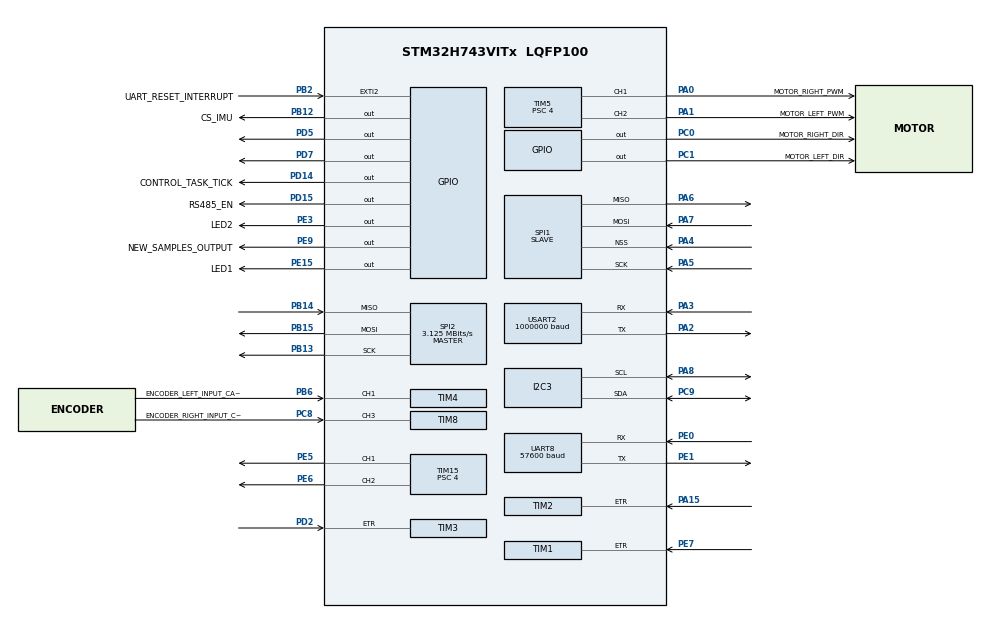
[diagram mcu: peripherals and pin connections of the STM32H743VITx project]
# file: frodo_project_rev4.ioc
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CORTEX_M7.default_mode_Activation=0
Dma.MEMTOMEM.4.Direction=DMA_MEMORY_TO_MEMORY
Dma.MEMTOMEM.4.EventEnable=DISABLE
Dma.MEMTOMEM.4.FIFOMode=DMA_FIFOMODE_ENABLE
Dma.MEMTOMEM.4.FIFOThreshold=DMA_FIFO_THRESHOLD_FULL
Dma.MEMTOMEM.4.Instance=DMA2_Stream0
Dma.MEMTOMEM.4.MemBurst=DMA_MBURST_SINGLE
Dma.MEMTOMEM.4.MemDataAlignment=DMA_MDATAALIGN_BYTE
Dma.MEMTOMEM.4.MemInc=DMA_MINC_ENABLE
Dma.MEMTOMEM.4.Mode=DMA_NORMAL
Dma.MEMTOMEM.4.PeriphBurst=DMA_PBURST_SINGLE
Dma.MEMTOMEM.4.PeriphDataAlignment=DMA_PDATAALIGN_BYTE
Dma.MEMTOMEM.4.PeriphInc=DMA_PINC_ENABLE
Dma.MEMTOMEM.4.Polarity=HAL_DMAMUX_REQ_GEN_RISING
Dma.MEMTOMEM.4.Priority=DMA_PRIORITY_VERY_HIGH
Dma.MEMTOMEM.4.RequestNumber=1
Dma.MEMTOMEM.4.SignalID=NONE
Dma.MEMTOMEM.4.SyncEnable=DISABLE
Dma.MEMTOMEM.4.SyncPolarity=HAL_DMAMUX_SYNC_NO_EVENT
Dma.MEMTOMEM.4.SyncRequestNumber=1
Dma.MEMTOMEM.4.SyncSignalID=NONE
Dma.Request0=UART8_RX
Dma.Request1=UART8_TX
Dma.Request2=USART2_RX
Dma.Request3=USART2_TX
Dma.Request4=MEMTOMEM
Dma.Request5=SPI1_RX
Dma.Request6=SPI1_TX
Dma.SPI1_RX.5.Direction=DMA_PERIPH_TO_MEMORY
Dma.SPI1_RX.5.EventEnable=DISABLE
Dma.SPI1_RX.5.FIFOMode=DMA_FIFOMODE_DISABLE
Dma.SPI1_RX.5.Instance=DMA1_Stream6
Dma.SPI1_RX.5.MemDataAlignment=DMA_MDATAALIGN_BYTE
Dma.SPI1_RX.5.MemInc=DMA_MINC_ENABLE
Dma.SPI1_RX.5.Mode=DMA_NORMAL
Dma.SPI1_RX.5.PeriphDataAlignment=DMA_PDATAALIGN_BYTE
Dma.SPI1_RX.5.PeriphInc=DMA_PINC_DISABLE
Dma.SPI1_RX.5.Polarity=HAL_DMAMUX_REQ_GEN_RISING
Dma.SPI1_RX.5.Priority=DMA_PRIORITY_LOW
Dma.SPI1_RX.5.RequestNumber=1
Dma.SPI1_RX.5.SignalID=NONE
Dma.SPI1_RX.5.SyncEnable=DISABLE
Dma.SPI1_RX.5.SyncPolarity=HAL_DMAMUX_SYNC_NO_EVENT
Dma.SPI1_RX.5.SyncRequestNumber=1
Dma.SPI1_RX.5.SyncSignalID=NONE
Dma.SPI1_TX.6.Direction=DMA_MEMORY_TO_PERIPH
Dma.SPI1_TX.6.EventEnable=DISABLE
Dma.SPI1_TX.6.FIFOMode=DMA_FIFOMODE_DISABLE
Dma.SPI1_TX.6.Instance=DMA1_Stream7
Dma.SPI1_TX.6.MemDataAlignment=DMA_MDATAALIGN_BYTE
Dma.SPI1_TX.6.MemInc=DMA_MINC_ENABLE
Dma.SPI1_TX.6.Mode=DMA_NORMAL
Dma.SPI1_TX.6.PeriphDataAlignment=DMA_PDATAALIGN_BYTE
Dma.SPI1_TX.6.PeriphInc=DMA_PINC_DISABLE
Dma.SPI1_TX.6.Polarity=HAL_DMAMUX_REQ_GEN_RISING
Dma.SPI1_TX.6.Priority=DMA_PRIORITY_LOW
Dma.SPI1_TX.6.RequestNumber=1
Dma.SPI1_TX.6.SignalID=NONE
Dma.SPI1_TX.6.SyncEnable=DISABLE
Dma.SPI1_TX.6.SyncPolarity=HAL_DMAMUX_SYNC_NO_EVENT
Dma.SPI1_TX.6.SyncRequestNumber=1
Dma.SPI1_TX.6.SyncSignalID=NONE
Dma.UART8_RX.0.Direction=DMA_PERIPH_TO_MEMORY
Dma.UART8_RX.0.EventEnable=DISABLE
Dma.UART8_RX.0.FIFOMode=DMA_FIFOMODE_DISABLE
Dma.UART8_RX.0.Instance=DMA1_Stream2
Dma.UART8_RX.0.MemDataAlignment=DMA_MDATAALIGN_BYTE
Dma.UART8_RX.0.MemInc=DMA_MINC_ENABLE
Dma.UART8_RX.0.Mode=DMA_NORMAL
Dma.UART8_RX.0.PeriphDataAlignment=DMA_PDATAALIGN_BYTE
Dma.UART8_RX.0.PeriphInc=DMA_PINC_DISABLE
Dma.UART8_RX.0.Polarity=HAL_DMAMUX_REQ_GEN_RISING
Dma.UART8_RX.0.Priority=DMA_PRIORITY_LOW
Dma.UART8_RX.0.RequestNumber=1
Dma.UART8_RX.0.SignalID=NONE
Dma.UART8_RX.0.SyncEnable=DISABLE
Dma.UART8_RX.0.SyncPolarity=HAL_DMAMUX_SYNC_NO_EVENT
Dma.UART8_RX.0.SyncRequestNumber=1
Dma.UART8_RX.0.SyncSignalID=NONE
Dma.UART8_TX.1.Direction=DMA_MEMORY_TO_PERIPH
Dma.UART8_TX.1.EventEnable=DISABLE
Dma.UART8_TX.1.FIFOMode=DMA_FIFOMODE_DISABLE
Dma.UART8_TX.1.Instance=DMA1_Stream3
Dma.UART8_TX.1.MemDataAlignment=DMA_MDATAALIGN_BYTE
Dma.UART8_TX.1.MemInc=DMA_MINC_ENABLE
Dma.UART8_TX.1.Mode=DMA_NORMAL
Dma.UART8_TX.1.PeriphDataAlignment=DMA_PDATAALIGN_BYTE
Dma.UART8_TX.1.PeriphInc=DMA_PINC_DISABLE
Dma.UART8_TX.1.Polarity=HAL_DMAMUX_REQ_GEN_RISING
Dma.UART8_TX.1.Priority=DMA_PRIORITY_LOW
Dma.UART8_TX.1.RequestNumber=1
Dma.UART8_TX.1.SignalID=NONE
Dma.UART8_TX.1.SyncEnable=DISABLE
Dma.UART8_TX.1.SyncPolarity=HAL_DMAMUX_SYNC_NO_EVENT
Dma.UART8_TX.1.SyncRequestNumber=1
Dma.UART8_TX.1.SyncSignalID=NONE
Dma.USART2_RX.2.Direction=DMA_PERIPH_TO_MEMORY
Dma.USART2_RX.2.EventEnable=DISABLE
Dma.USART2_RX.2.FIFOMode=DMA_FIFOMODE_DISABLE
Dma.USART2_RX.2.Instance=DMA1_Stream4
Dma.USART2_RX.2.MemDataAlignment=DMA_MDATAALIGN_BYTE
Dma.USART2_RX.2.MemInc=DMA_MINC_ENABLE
Dma.USART2_RX.2.Mode=DMA_NORMAL
Dma.USART2_RX.2.PeriphDataAlignment=DMA_PDATAALIGN_BYTE
Dma.USART2_RX.2.PeriphInc=DMA_PINC_DISABLE
Dma.USART2_RX.2.Polarity=HAL_DMAMUX_REQ_GEN_RISING
Dma.USART2_RX.2.Priority=DMA_PRIORITY_LOW
Dma.USART2_RX.2.RequestNumber=1
Dma.USART2_RX.2.SignalID=NONE
Dma.USART2_RX.2.SyncEnable=DISABLE
Dma.USART2_RX.2.SyncPolarity=HAL_DMAMUX_SYNC_NO_EVENT
Dma.USART2_RX.2.SyncRequestNumber=1
Dma.USART2_RX.2.SyncSignalID=NONE
Dma.USART2_TX.3.Direction=DMA_MEMORY_TO_PERIPH
Dma.USART2_TX.3.EventEnable=DISABLE
Dma.USART2_TX.3.FIFOMode=DMA_FIFOMODE_DISABLE
Dma.USART2_TX.3.Instance=DMA1_Stream5
Dma.USART2_TX.3.MemDataAlignment=DMA_MDATAALIGN_BYTE
Dma.USART2_TX.3.MemInc=DMA_MINC_ENABLE
Dma.USART2_TX.3.Mode=DMA_NORMAL
Dma.USART2_TX.3.PeriphDataAlignment=DMA_PDATAALIGN_BYTE
Dma.USART2_TX.3.PeriphInc=DMA_PINC_DISABLE
Dma.USART2_TX.3.Polarity=HAL_DMAMUX_REQ_GEN_RISING
Dma.USART2_TX.3.Priority=DMA_PRIORITY_LOW
Dma.USART2_TX.3.RequestNumber=1
Dma.USART2_TX.3.SignalID=NONE
Dma.USART2_TX.3.SyncEnable=DISABLE
Dma.USART2_TX.3.SyncPolarity=HAL_DMAMUX_SYNC_NO_EVENT
Dma.USART2_TX.3.SyncRequestNumber=1
Dma.USART2_TX.3.SyncSignalID=NONE
FREERTOS.Tasks01=defaultTask,24,128,StartDefaultTask,Default,NULL,Dynamic,NULL,NULL
FREERTOS.Timers01=myTimer02,Callback01,osTimerPeriodic,Default,NULL,Dynamic,NULL
FREERTOS.configTOTAL_HEAP_SIZE=120000
FREERTOS.configUSE_NEWLIB_REENTRANT=1
I2C3.I2C_Rise_Time=0
I2C3.Timing=0x10C0ECFF
Mcu.Family=STM32H7
Mcu.Name=STM32H743VITx
Mcu.Package=LQFP100
NVIC.DMA1_Stream2_IRQn=true\:5\:0\:false\:false\:true\:true\:false\:true\:true
NVIC.DMA1_Stream3_IRQn=true\:5\:0\:false\:false\:true\:true\:false\:true\:true
NVIC.DMA1_Stream4_IRQn=true\:5\:0\:false\:false\:true\:true\:false\:true\:true
NVIC.DMA1_Stream5_IRQn=true\:5\:0\:false\:false\:true\:true\:false\:true\:true
NVIC.DMA1_Stream6_IRQn=true\:5\:0\:false\:false\:true\:true\:false\:true\:true
NVIC.DMA1_Stream7_IRQn=true\:5\:0\:false\:false\:true\:true\:false\:true\:true
NVIC.DMA2_Stream0_IRQn=true\:5\:0\:false\:false\:true\:true\:true\:true\:true
NVIC.EXTI2_IRQn=true\:5\:0\:false\:false\:true\:true\:true\:true\:true
NVIC.I2C3_ER_IRQn=true\:5\:0\:false\:false\:true\:true\:true\:true\:true
NVIC.I2C3_EV_IRQn=true\:5\:0\:false\:false\:true\:true\:true\:true\:true
NVIC.PriorityGroup=NVIC_PRIORITYGROUP_4
NVIC.SPI1_IRQn=true\:5\:0\:false\:false\:true\:true\:true\:true\:true
NVIC.TIM2_IRQn=true\:5\:0\:false\:false\:true\:true\:true\:true\:true
NVIC.TIM4_IRQn=true\:5\:0\:false\:false\:true\:true\:true\:true\:true
NVIC.TIM6_DAC_IRQn=true\:15\:0\:false\:false\:true\:false\:false\:true\:true
NVIC.TimeBase=TIM6_DAC_IRQn
NVIC.TimeBaseIP=TIM6
NVIC.UART8_IRQn=true\:5\:0\:false\:false\:true\:true\:true\:true\:true
NVIC.USART2_IRQn=true\:5\:0\:false\:false\:true\:true\:true\:true\:true
PA0.GPIO_Label=MOTOR_RIGHT_PWM
PA0.Signal=S_TIM5_CH1
PA1.GPIO_Label=MOTOR_LEFT_PWM
PA1.Signal=S_TIM5_CH2
PA10.Signal=USART1_RX
PA13\ (JTMS/SWDIO).Mode=Serial_Wire
PA13\ (JTMS/SWDIO).Signal=DEBUG_JTMS-SWDIO
PA14\ (JTCK/SWCLK).Mode=Serial_Wire
PA14\ (JTCK/SWCLK).Signal=DEBUG_JTCK-SWCLK
PA15\ (JTDI).Signal=S_TIM2_CH1_ETR
PA2.Mode=Asynchronous
PA2.Signal=USART2_TX
PA3.Mode=Asynchronous
PA3.Signal=USART2_RX
PA4.Mode=NSS_Signal_Hard_Input
PA4.Signal=SPI1_NSS
PA5.Mode=Full_Duplex_Slave
PA5.Signal=SPI1_SCK
PA6.Mode=Full_Duplex_Slave
PA6.Signal=SPI1_MISO
PA7.Mode=Full_Duplex_Slave
PA7.Signal=SPI1_MOSI
PA8.Mode=I2C
PA8.Signal=I2C3_SCL
PA9.Signal=USART1_TX
PB12.GPIO_Label=CS_IMU
PB12.Signal=GPIO_Output
PB13.Mode=Full_Duplex_Master
PB13.Signal=SPI2_SCK
PB14.Mode=Full_Duplex_Master
PB14.Signal=SPI2_MISO
PB15.Mode=Full_Duplex_Master
PB15.Signal=SPI2_MOSI
PB2.GPIO_Label=UART_RESET_INTERRUPT
PB2.GPIO_ModeDefaultEXTI=GPIO_MODE_IT_RISING_FALLING
PB2.GPIO_PuPd=GPIO_PULLDOWN
PB2.Signal=GPXTI2
PB6.GPIO_Label=ENCODER_LEFT_INPUT_CAPTURE
PB6.Signal=S_TIM4_CH1
PC0.GPIO_Label=MOTOR_RIGHT_DIR
PC0.Signal=GPIO_Output
PC1.GPIO_Label=MOTOR_LEFT_DIR
PC1.Signal=GPIO_Output
PC8.GPIO_Label=ENCODER_RIGHT_INPUT_CAPTURE
PC8.Signal=S_TIM8_CH3
PC9.Mode=I2C
PC9.Signal=I2C3_SDA
PD14.GPIO_Label=CONTROL_TASK_TICK
PD14.Signal=GPIO_Output
PD15.GPIO_Label=RS485_EN
PD15.Signal=GPIO_Output
PD2.Signal=S_TIM3_ETR
PD5.Signal=GPIO_Output
PD7.Signal=GPIO_Output
PE0.Mode=Asynchronous
PE0.Signal=UART8_RX
PE1.Mode=Asynchronous
PE1.Signal=UART8_TX
PE15.GPIO_Label=LED1
PE15.Signal=GPIO_Output
PE3.GPIO_Label=LED2
PE3.Signal=GPIO_Output
PE5.Signal=S_TIM15_CH1
PE6.Signal=S_TIM15_CH2
PE7.Signal=S_TIM1_ETR
PE9.GPIO_Label=NEW_SAMPLES_OUTPUT
PE9.GPIO_PuPd=GPIO_PULLDOWN
PE9.Signal=GPIO_Output
PH0-OSC_IN\ (PH0).Mode=HSE-External-Oscillator
PH0-OSC_IN\ (PH0).Signal=RCC_OSC_IN
PH1-OSC_OUT\ (PH1).Mode=HSE-External-Oscillator
PH1-OSC_OUT\ (PH1).Signal=RCC_OSC_OUT
ProjectManager.HeapSize=0x200
ProjectManager.StackSize=0x400
ProjectManager.TargetToolchain=STM32CubeIDE
RCC.ADCFreq_Value=75000000
RCC.APB1Freq_Value=100000000
RCC.APB2Freq_Value=100000000
RCC.APB3Freq_Value=100000000
RCC.APB4Freq_Value=100000000
RCC.CortexFreq_Value=400000000
RCC.D1PPRE=RCC_APB3_DIV2
RCC.D2PPRE1=RCC_APB1_DIV2
RCC.D2PPRE2=RCC_APB2_DIV2
RCC.D3PPRE=RCC_APB4_DIV2
RCC.DIVM1=2
RCC.DIVM2=2
RCC.DIVN1=64
RCC.DIVN2=12
RCC.DIVQ1=4
RCC.FDCANCLockSelection=RCC_FDCANCLKSOURCE_PLL2
RCC.HCLKFreq_Value=200000000
RCC.HPRE=RCC_HCLK_DIV2
RCC.PLL2FRACN=0
RCC.PLLFRACN=0
RCC.PLLSourceVirtual=RCC_PLLSOURCE_HSE
RCC.PWR_Regulator_Voltage_Scale=PWR_REGULATOR_VOLTAGE_SCALE1
RCC.SYSCLKFreq_VALUE=400000000
RCC.SYSCLKSource=RCC_SYSCLKSOURCE_PLLCLK
RCC.USBFreq_Value=200000000
SH.S_TIM15_CH1.0=TIM15_CH1,PWM Generation1 CH1
SH.S_TIM15_CH2.0=TIM15_CH2,PWM Generation2 CH2
SH.S_TIM1_ETR.0=TIM1_ETR,TriggerSource_ETR
SH.S_TIM2_CH1_ETR.0=TIM2_ETR,TriggerSource_ETR
SH.S_TIM3_ETR.0=TIM3_ETR,TriggerSource_ETR
SH.S_TIM4_CH1.0=TIM4_CH1,Input_Capture1_from_TI1
SH.S_TIM5_CH1.0=TIM5_CH1,PWM Generation1 CH1
SH.S_TIM5_CH2.0=TIM5_CH2,PWM Generation2 CH2
SH.S_TIM8_CH3.0=TIM8_CH3,Input_Capture3_from_TI3
SPI1.DataSize=SPI_DATASIZE_8BIT
SPI1.Direction=SPI_DIRECTION_2LINES
SPI1.Mode=SPI_MODE_SLAVE
SPI1.VirtualNSS=VM_NSSHARD
SPI1.VirtualType=VM_SLAVE
SPI2.BaudRatePrescaler=SPI_BAUDRATEPRESCALER_64
SPI2.CalculateBaudRate=3.125 MBits/s
SPI2.DataSize=SPI_DATASIZE_8BIT
SPI2.Direction=SPI_DIRECTION_2LINES
SPI2.Mode=SPI_MODE_MASTER
SPI2.VirtualType=VM_MASTER
TIM15.Channel-PWM\ Generation1\ CH1=TIM_CHANNEL_1
TIM15.Channel-PWM\ Generation2\ CH2=TIM_CHANNEL_2
TIM15.Period=40000
TIM15.Prescaler=4
TIM4.Channel-Input_Capture1_from_TI1=TIM_CHANNEL_1
TIM4.ICPolarity_CH1=TIM_INPUTCHANNELPOLARITY_RISING
TIM4.Prescaler=199
TIM5.Channel-PWM\ Generation1\ CH1=TIM_CHANNEL_1
TIM5.Channel-PWM\ Generation2\ CH2=TIM_CHANNEL_2
TIM5.Period=40000
TIM5.Prescaler=4
TIM8.Channel-Input_Capture3_from_TI3=TIM_CHANNEL_3
TIM8.Prescaler=199
UART8.BaudRate=57600
UART8.Parity=PARITY_EVEN
UART8.WordLength=WORDLENGTH_9B
USART2.BaudRate=1000000
USART2.VirtualMode-Asynchronous=VM_ASYNC
VP_FREERTOS_VS_CMSIS_V2.Mode=CMSIS_V2
VP_MEMORYMAP_VS_MEMORYMAP.Mode=CurAppReg
VP_SYS_VS_tim6.Mode=TIM6
VP_TIM1_VS_ControllerModeClock.Mode=Clock Mode
VP_TIM2_VS_ControllerModeClock.Mode=Clock Mode
VP_TIM3_VS_ControllerModeClock.Mode=Clock Mode
VP_TIM4_VS_ClockSourceINT.Mode=Internal
VP_TIM5_VS_ClockSourceINT.Mode=Internal
VP_TIM8_VS_ClockSourceINT.Mode=Internal
board=custom

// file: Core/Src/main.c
/* USER CODE BEGIN Header */
/**
  ******************************************************************************
  * @file           : main.c
  * @brief          : Main program body
  ******************************************************************************
  * @attention
  *
  * Copyright (c) 2025 STMicroelectronics.
  * All rights reserved.
  *
  * This software is licensed under terms that can be found in the LICENSE file
  * in the root directory of this software component.
  * If no LICENSE file comes with this software, it is provided AS-IS.
  *
  ******************************************************************************
  */
/* USER CODE END Header */
#include "main.h"
#include "cmsis_os.h"

I2C_HandleTypeDef hi2c3;

SPI_HandleTypeDef hspi1;
SPI_HandleTypeDef hspi2;
DMA_HandleTypeDef hdma_spi1_rx;
DMA_HandleTypeDef hdma_spi1_tx;

TIM_HandleTypeDef htim1;
TIM_HandleTypeDef htim2;
TIM_HandleTypeDef htim3;
TIM_HandleTypeDef htim4;
TIM_HandleTypeDef htim5;
TIM_HandleTypeDef htim8;
TIM_HandleTypeDef htim15;

UART_HandleTypeDef huart8;
UART_HandleTypeDef huart2;
DMA_HandleTypeDef hdma_uart8_rx;
DMA_HandleTypeDef hdma_uart8_tx;
DMA_HandleTypeDef hdma_usart2_rx;
DMA_HandleTypeDef hdma_usart2_tx;

DMA_HandleTypeDef hdma_memtomem_dma2_stream0;
/* Definitions for defaultTask */
osThreadId_t defaultTaskHandle;
const osThreadAttr_t defaultTask_attributes = {
  .name = "defaultTask",
  .stack_size = 128 * 4,
  .priority = (osPriority_t) osPriorityNormal,
};
/* Definitions for myTimer02 */
osTimerId_t myTimer02Handle;
const osTimerAttr_t myTimer02_attributes = {
  .name = "myTimer02"
};

void SystemClock_Config(void);
static void MX_GPIO_Init(void);
static void MX_DMA_Init(void);
static void MX_SPI2_Init(void);
static void MX_UART8_Init(void);
static void MX_USART2_UART_Init(void);
static void MX_TIM2_Init(void);
static void MX_SPI1_Init(void);
static void MX_I2C3_Init(void);
static void MX_TIM5_Init(void);
static void MX_TIM3_Init(void);
static void MX_TIM4_Init(void);
static void MX_TIM8_Init(void);
static void MX_TIM15_Init(void);
static void MX_TIM1_Init(void);
void StartDefaultTask(void *argument);
void Callback01(void *argument);

int main(void)
{

  /* MCU Configuration--------------------------------------------------------*/

  /* Reset of all peripherals, Initializes the Flash interface and the Systick. */
  HAL_Init();

  /* Configure the system clock */
  SystemClock_Config();

  /* Initialize all configured peripherals */
  MX_GPIO_Init();
  MX_DMA_Init();
  MX_SPI2_Init();
  MX_UART8_Init();
  MX_USART2_UART_Init();
  MX_TIM2_Init();
  MX_SPI1_Init();
  MX_I2C3_Init();
  MX_TIM5_Init();
  MX_TIM3_Init();
  MX_TIM4_Init();
  MX_TIM8_Init();
  MX_TIM15_Init();
  MX_TIM1_Init();

  /* Init scheduler */
  osKernelInitialize();

  /* Create the timer(s) */
  /* creation of myTimer02 */
  myTimer02Handle = osTimerNew(Callback01, osTimerPeriodic, NULL, &myTimer02_attributes);

  /* USER CODE BEGIN RTOS_QUEUES */
  firmware();
  /* add queues, ... */
  /* USER CODE END RTOS_QUEUES */

  /* Create the thread(s) */
  /* creation of defaultTask */
  defaultTaskHandle = osThreadNew(StartDefaultTask, NULL, &defaultTask_attributes);

  /* Start scheduler */
  osKernelStart();

  /* We should never get here as control is now taken by the scheduler */

  /* Infinite loop */
  while (1)
  {

  }
}

void SystemClock_Config(void)
{
  RCC_OscInitTypeDef RCC_OscInitStruct = {0};
  RCC_ClkInitTypeDef RCC_ClkInitStruct = {0};

  /** Supply configuration update enable
  */
  HAL_PWREx_ConfigSupply(PWR_LDO_SUPPLY);

  /** Configure the main internal regulator output voltage
  */
  __HAL_PWR_VOLTAGESCALING_CONFIG(PWR_REGULATOR_VOLTAGE_SCALE1);

  while(!__HAL_PWR_GET_FLAG(PWR_FLAG_VOSRDY)) {}

  /** Initializes the RCC Oscillators according to the specified parameters
  * in the RCC_OscInitTypeDef structure.
  */
  RCC_OscInitStruct.OscillatorType = RCC_OSCILLATORTYPE_HSE;
  RCC_OscInitStruct.HSEState = RCC_HSE_ON;
  RCC_OscInitStruct.PLL.PLLState = RCC_PLL_ON;
  RCC_OscInitStruct.PLL.PLLSource = RCC_PLLSOURCE_HSE;
  RCC_OscInitStruct.PLL.PLLM = 2;
  RCC_OscInitStruct.PLL.PLLN = 64;
  RCC_OscInitStruct.PLL.PLLP = 2;
  RCC_OscInitStruct.PLL.PLLQ = 4;
  RCC_OscInitStruct.PLL.PLLR = 2;
  RCC_OscInitStruct.PLL.PLLRGE = RCC_PLL1VCIRANGE_3;
  RCC_OscInitStruct.PLL.PLLVCOSEL = RCC_PLL1VCOWIDE;
  RCC_OscInitStruct.PLL.PLLFRACN = 0;
  if (HAL_RCC_OscConfig(&RCC_OscInitStruct) != HAL_OK)
  {
    Error_Handler();
  }

  /** Initializes the CPU, AHB and APB buses clocks
  */
  RCC_ClkInitStruct.ClockType = RCC_CLOCKTYPE_HCLK|RCC_CLOCKTYPE_SYSCLK
                              |RCC_CLOCKTYPE_PCLK1|RCC_CLOCKTYPE_PCLK2
                              |RCC_CLOCKTYPE_D3PCLK1|RCC_CLOCKTYPE_D1PCLK1;
  RCC_ClkInitStruct.SYSCLKSource = RCC_SYSCLKSOURCE_PLLCLK;
  RCC_ClkInitStruct.SYSCLKDivider = RCC_SYSCLK_DIV1;
  RCC_ClkInitStruct.AHBCLKDivider = RCC_HCLK_DIV2;
  RCC_ClkInitStruct.APB3CLKDivider = RCC_APB3_DIV2;
  RCC_ClkInitStruct.APB1CLKDivider = RCC_APB1_DIV2;
  RCC_ClkInitStruct.APB2CLKDivider = RCC_APB2_DIV2;
  RCC_ClkInitStruct.APB4CLKDivider = RCC_APB4_DIV2;

  if (HAL_RCC_ClockConfig(&RCC_ClkInitStruct, FLASH_LATENCY_2) != HAL_OK)
  {
    Error_Handler();
  }
}

static void MX_I2C3_Init(void)
{

  hi2c3.Instance = I2C3;
  hi2c3.Init.Timing = 0x10C0ECFF;
  hi2c3.Init.OwnAddress1 = 0;
  hi2c3.Init.AddressingMode = I2C_ADDRESSINGMODE_7BIT;
  hi2c3.Init.DualAddressMode = I2C_DUALADDRESS_DISABLE;
  hi2c3.Init.OwnAddress2 = 0;
  hi2c3.Init.OwnAddress2Masks = I2C_OA2_NOMASK;
  hi2c3.Init.GeneralCallMode = I2C_GENERALCALL_DISABLE;
  hi2c3.Init.NoStretchMode = I2C_NOSTRETCH_DISABLE;
  if (HAL_I2C_Init(&hi2c3) != HAL_OK)
  {
    Error_Handler();
  }

  /** Configure Analogue filter
  */
  if (HAL_I2CEx_ConfigAnalogFilter(&hi2c3, I2C_ANALOGFILTER_ENABLE) != HAL_OK)
  {
    Error_Handler();
  }

  /** Configure Digital filter
  */
  if (HAL_I2CEx_ConfigDigitalFilter(&hi2c3, 0) != HAL_OK)
  {
    Error_Handler();
  }

}

static void MX_SPI1_Init(void)
{

  /* SPI1 parameter configuration*/
  hspi1.Instance = SPI1;
  hspi1.Init.Mode = SPI_MODE_SLAVE;
  hspi1.Init.Direction = SPI_DIRECTION_2LINES;
  hspi1.Init.DataSize = SPI_DATASIZE_8BIT;
  hspi1.Init.CLKPolarity = SPI_POLARITY_LOW;
  hspi1.Init.CLKPhase = SPI_PHASE_1EDGE;
  hspi1.Init.NSS = SPI_NSS_HARD_INPUT;
  hspi1.Init.FirstBit = SPI_FIRSTBIT_MSB;
  hspi1.Init.TIMode = SPI_TIMODE_DISABLE;
  hspi1.Init.CRCCalculation = SPI_CRCCALCULATION_DISABLE;
  hspi1.Init.CRCPolynomial = 0x0;
  hspi1.Init.NSSPMode = SPI_NSS_PULSE_DISABLE;
  hspi1.Init.NSSPolarity = SPI_NSS_POLARITY_LOW;
  hspi1.Init.FifoThreshold = SPI_FIFO_THRESHOLD_01DATA;
  hspi1.Init.TxCRCInitializationPattern = SPI_CRC_INITIALIZATION_ALL_ZERO_PATTERN;
  hspi1.Init.RxCRCInitializationPattern = SPI_CRC_INITIALIZATION_ALL_ZERO_PATTERN;
  hspi1.Init.MasterSSIdleness = SPI_MASTER_SS_IDLENESS_00CYCLE;
  hspi1.Init.MasterInterDataIdleness = SPI_MASTER_INTERDATA_IDLENESS_00CYCLE;
  hspi1.Init.MasterReceiverAutoSusp = SPI_MASTER_RX_AUTOSUSP_DISABLE;
  hspi1.Init.MasterKeepIOState = SPI_MASTER_KEEP_IO_STATE_DISABLE;
  hspi1.Init.IOSwap = SPI_IO_SWAP_DISABLE;
  if (HAL_SPI_Init(&hspi1) != HAL_OK)
  {
    Error_Handler();
  }

}

static void MX_SPI2_Init(void)
{

  /* SPI2 parameter configuration*/
  hspi2.Instance = SPI2;
  hspi2.Init.Mode = SPI_MODE_MASTER;
  hspi2.Init.Direction = SPI_DIRECTION_2LINES;
  hspi2.Init.DataSize = SPI_DATASIZE_8BIT;
  hspi2.Init.CLKPolarity = SPI_POLARITY_LOW;
  hspi2.Init.CLKPhase = SPI_PHASE_1EDGE;
  hspi2.Init.NSS = SPI_NSS_SOFT;
  hspi2.Init.BaudRatePrescaler = SPI_BAUDRATEPRESCALER_64;
  hspi2.Init.FirstBit = SPI_FIRSTBIT_MSB;
  hspi2.Init.TIMode = SPI_TIMODE_DISABLE;
  hspi2.Init.CRCCalculation = SPI_CRCCALCULATION_DISABLE;
  hspi2.Init.CRCPolynomial = 0x0;
  hspi2.Init.NSSPMode = SPI_NSS_PULSE_ENABLE;
  hspi2.Init.NSSPolarity = SPI_NSS_POLARITY_LOW;
  hspi2.Init.FifoThreshold = SPI_FIFO_THRESHOLD_01DATA;
  hspi2.Init.TxCRCInitializationPattern = SPI_CRC_INITIALIZATION_ALL_ZERO_PATTERN;
  hspi2.Init.RxCRCInitializationPattern = SPI_CRC_INITIALIZATION_ALL_ZERO_PATTERN;
  hspi2.Init.MasterSSIdleness = SPI_MASTER_SS_IDLENESS_00CYCLE;
  hspi2.Init.MasterInterDataIdleness = SPI_MASTER_INTERDATA_IDLENESS_00CYCLE;
  hspi2.Init.MasterReceiverAutoSusp = SPI_MASTER_RX_AUTOSUSP_DISABLE;
  hspi2.Init.MasterKeepIOState = SPI_MASTER_KEEP_IO_STATE_DISABLE;
  hspi2.Init.IOSwap = SPI_IO_SWAP_DISABLE;
  if (HAL_SPI_Init(&hspi2) != HAL_OK)
  {
    Error_Handler();
  }

}

static void MX_TIM1_Init(void)
{

  TIM_SlaveConfigTypeDef sSlaveConfig = {0};
  TIM_MasterConfigTypeDef sMasterConfig = {0};

  htim1.Instance = TIM1;
  htim1.Init.Prescaler = 0;
  htim1.Init.CounterMode = TIM_COUNTERMODE_UP;
  htim1.Init.Period = 65535;
  htim1.Init.ClockDivision = TIM_CLOCKDIVISION_DIV1;
  htim1.Init.RepetitionCounter = 0;
  htim1.Init.AutoReloadPreload = TIM_AUTORELOAD_PRELOAD_DISABLE;
  if (HAL_TIM_Base_Init(&htim1) != HAL_OK)
  {
    Error_Handler();
  }
  sSlaveConfig.SlaveMode = TIM_SLAVEMODE_EXTERNAL1;
  sSlaveConfig.InputTrigger = TIM_TS_ETRF;
  sSlaveConfig.TriggerPolarity = TIM_TRIGGERPOLARITY_NONINVERTED;
  sSlaveConfig.TriggerPrescaler = TIM_TRIGGERPRESCALER_DIV1;
  sSlaveConfig.TriggerFilter = 0;
  if (HAL_TIM_SlaveConfigSynchro(&htim1, &sSlaveConfig) != HAL_OK)
  {
    Error_Handler();
  }
  sMasterConfig.MasterOutputTrigger = TIM_TRGO_RESET;
  sMasterConfig.MasterOutputTrigger2 = TIM_TRGO2_RESET;
  sMasterConfig.MasterSlaveMode = TIM_MASTERSLAVEMODE_DISABLE;
  if (HAL_TIMEx_MasterConfigSynchronization(&htim1, &sMasterConfig) != HAL_OK)
  {
    Error_Handler();
  }

}

static void MX_TIM2_Init(void)
{

  TIM_SlaveConfigTypeDef sSlaveConfig = {0};
  TIM_MasterConfigTypeDef sMasterConfig = {0};

  htim2.Instance = TIM2;
  htim2.Init.Prescaler = 0;
  htim2.Init.CounterMode = TIM_COUNTERMODE_UP;
  htim2.Init.Period = 4294967295;
  htim2.Init.ClockDivision = TIM_CLOCKDIVISION_DIV1;
  htim2.Init.AutoReloadPreload = TIM_AUTORELOAD_PRELOAD_DISABLE;
  if (HAL_TIM_Base_Init(&htim2) != HAL_OK)
  {
    Error_Handler();
  }
  sSlaveConfig.SlaveMode = TIM_SLAVEMODE_EXTERNAL1;
  sSlaveConfig.InputTrigger = TIM_TS_ETRF;
  sSlaveConfig.TriggerPolarity = TIM_TRIGGERPOLARITY_NONINVERTED;
  sSlaveConfig.TriggerPrescaler = TIM_TRIGGERPRESCALER_DIV1;
  sSlaveConfig.TriggerFilter = 0;
  if (HAL_TIM_SlaveConfigSynchro(&htim2, &sSlaveConfig) != HAL_OK)
  {
    Error_Handler();
  }
  sMasterConfig.MasterOutputTrigger = TIM_TRGO_RESET;
  sMasterConfig.MasterSlaveMode = TIM_MASTERSLAVEMODE_DISABLE;
  if (HAL_TIMEx_MasterConfigSynchronization(&htim2, &sMasterConfig) != HAL_OK)
  {
    Error_Handler();
  }

}

static void MX_TIM3_Init(void)
{

  TIM_SlaveConfigTypeDef sSlaveConfig = {0};
  TIM_MasterConfigTypeDef sMasterConfig = {0};

  htim3.Instance = TIM3;
  htim3.Init.Prescaler = 0;
  htim3.Init.CounterMode = TIM_COUNTERMODE_UP;
  htim3.Init.Period = 65535;
  htim3.Init.ClockDivision = TIM_CLOCKDIVISION_DIV1;
  htim3.Init.AutoReloadPreload = TIM_AUTORELOAD_PRELOAD_DISABLE;
  if (HAL_TIM_Base_Init(&htim3) != HAL_OK)
  {
    Error_Handler();
  }
  sSlaveConfig.SlaveMode = TIM_SLAVEMODE_EXTERNAL1;
  sSlaveConfig.InputTrigger = TIM_TS_ETRF;
  sSlaveConfig.TriggerPolarity = TIM_TRIGGERPOLARITY_NONINVERTED;
  sSlaveConfig.TriggerPrescaler = TIM_TRIGGERPRESCALER_DIV1;
  sSlaveConfig.TriggerFilter = 0;
  if (HAL_TIM_SlaveConfigSynchro(&htim3, &sSlaveConfig) != HAL_OK)
  {
    Error_Handler();
  }
  sMasterConfig.MasterOutputTrigger = TIM_TRGO_RESET;
  sMasterConfig.MasterSlaveMode = TIM_MASTERSLAVEMODE_DISABLE;
  if (HAL_TIMEx_MasterConfigSynchronization(&htim3, &sMasterConfig) != HAL_OK)
  {
    Error_Handler();
  }

}

static void MX_TIM4_Init(void)
{

  TIM_ClockConfigTypeDef sClockSourceConfig = {0};
  TIM_MasterConfigTypeDef sMasterConfig = {0};
  TIM_IC_InitTypeDef sConfigIC = {0};

  htim4.Instance = TIM4;
  htim4.Init.Prescaler = 199;
  htim4.Init.CounterMode = TIM_COUNTERMODE_UP;
  htim4.Init.Period = 65535;
  htim4.Init.ClockDivision = TIM_CLOCKDIVISION_DIV1;
  htim4.Init.AutoReloadPreload = TIM_AUTORELOAD_PRELOAD_DISABLE;
  if (HAL_TIM_Base_Init(&htim4) != HAL_OK)
  {
    Error_Handler();
  }
  sClockSourceConfig.ClockSource = TIM_CLOCKSOURCE_INTERNAL;
  if (HAL_TIM_ConfigClockSource(&htim4, &sClockSourceConfig) != HAL_OK)
  {
    Error_Handler();
  }
  if (HAL_TIM_IC_Init(&htim4) != HAL_OK)
  {
    Error_Handler();
  }
  sMasterConfig.MasterOutputTrigger = TIM_TRGO_RESET;
  sMasterConfig.MasterSlaveMode = TIM_MASTERSLAVEMODE_DISABLE;
  if (HAL_TIMEx_MasterConfigSynchronization(&htim4, &sMasterConfig) != HAL_OK)
  {
    Error_Handler();
  }
  sConfigIC.ICPolarity = TIM_INPUTCHANNELPOLARITY_RISING;
  sConfigIC.ICSelection = TIM_ICSELECTION_DIRECTTI;
  sConfigIC.ICPrescaler = TIM_ICPSC_DIV1;
  sConfigIC.ICFilter = 0;
  if (HAL_TIM_IC_ConfigChannel(&htim4, &sConfigIC, TIM_CHANNEL_1) != HAL_OK)
  {
    Error_Handler();
  }

}

static void MX_TIM5_Init(void)
{

  TIM_ClockConfigTypeDef sClockSourceConfig = {0};
  TIM_MasterConfigTypeDef sMasterConfig = {0};
  TIM_OC_InitTypeDef sConfigOC = {0};

  htim5.Instance = TIM5;
  htim5.Init.Prescaler = 4;
  htim5.Init.CounterMode = TIM_COUNTERMODE_UP;
  htim5.Init.Period = 40000;
  htim5.Init.ClockDivision = TIM_CLOCKDIVISION_DIV1;
  htim5.Init.AutoReloadPreload = TIM_AUTORELOAD_PRELOAD_DISABLE;
  if (HAL_TIM_Base_Init(&htim5) != HAL_OK)
  {
    Error_Handler();
  }
  sClockSourceConfig.ClockSource = TIM_CLOCKSOURCE_INTERNAL;
  if (HAL_TIM_ConfigClockSource(&htim5, &sClockSourceConfig) != HAL_OK)
  {
    Error_Handler();
  }
  if (HAL_TIM_PWM_Init(&htim5) != HAL_OK)
  {
    Error_Handler();
  }
  sMasterConfig.MasterOutputTrigger = TIM_TRGO_RESET;
  sMasterConfig.MasterSlaveMode = TIM_MASTERSLAVEMODE_DISABLE;
  if (HAL_TIMEx_MasterConfigSynchronization(&htim5, &sMasterConfig) != HAL_OK)
  {
    Error_Handler();
  }
  sConfigOC.OCMode = TIM_OCMODE_PWM1;
  sConfigOC.Pulse = 0;
  sConfigOC.OCPolarity = TIM_OCPOLARITY_HIGH;
  sConfigOC.OCFastMode = TIM_OCFAST_DISABLE;
  if (HAL_TIM_PWM_ConfigChannel(&htim5, &sConfigOC, TIM_CHANNEL_1) != HAL_OK)
  {
    Error_Handler();
  }
  if (HAL_TIM_PWM_ConfigChannel(&htim5, &sConfigOC, TIM_CHANNEL_2) != HAL_OK)
  {
    Error_Handler();
  }
  HAL_TIM_MspPostInit(&htim5);

}

static void MX_TIM8_Init(void)
{

  TIM_ClockConfigTypeDef sClockSourceConfig = {0};
  TIM_MasterConfigTypeDef sMasterConfig = {0};
  TIM_IC_InitTypeDef sConfigIC = {0};

  htim8.Instance = TIM8;
  htim8.Init.Prescaler = 199;
  htim8.Init.CounterMode = TIM_COUNTERMODE_UP;
  htim8.Init.Period = 65535;
  htim8.Init.ClockDivision = TIM_CLOCKDIVISION_DIV1;
  htim8.Init.RepetitionCounter = 0;
  htim8.Init.AutoReloadPreload = TIM_AUTORELOAD_PRELOAD_DISABLE;
  if (HAL_TIM_Base_Init(&htim8) != HAL_OK)
  {
    Error_Handler();
  }
  sClockSourceConfig.ClockSource = TIM_CLOCKSOURCE_INTERNAL;
  if (HAL_TIM_ConfigClockSource(&htim8, &sClockSourceConfig) != HAL_OK)
  {
    Error_Handler();
  }
  if (HAL_TIM_IC_Init(&htim8) != HAL_OK)
  {
    Error_Handler();
  }
  sMasterConfig.MasterOutputTrigger = TIM_TRGO_RESET;
  sMasterConfig.MasterOutputTrigger2 = TIM_TRGO2_RESET;
  sMasterConfig.MasterSlaveMode = TIM_MASTERSLAVEMODE_DISABLE;
  if (HAL_TIMEx_MasterConfigSynchronization(&htim8, &sMasterConfig) != HAL_OK)
  {
    Error_Handler();
  }
  sConfigIC.ICPolarity = TIM_INPUTCHANNELPOLARITY_RISING;
  sConfigIC.ICSelection = TIM_ICSELECTION_DIRECTTI;
  sConfigIC.ICPrescaler = TIM_ICPSC_DIV1;
  sConfigIC.ICFilter = 0;
  if (HAL_TIM_IC_ConfigChannel(&htim8, &sConfigIC, TIM_CHANNEL_3) != HAL_OK)
  {
    Error_Handler();
  }

}

static void MX_TIM15_Init(void)
{

  TIM_MasterConfigTypeDef sMasterConfig = {0};
  TIM_OC_InitTypeDef sConfigOC = {0};
  TIM_BreakDeadTimeConfigTypeDef sBreakDeadTimeConfig = {0};

  htim15.Instance = TIM15;
  htim15.Init.Prescaler = 4;
  htim15.Init.CounterMode = TIM_COUNTERMODE_UP;
  htim15.Init.Period = 40000;
  htim15.Init.ClockDivision = TIM_CLOCKDIVISION_DIV1;
  htim15.Init.RepetitionCounter = 0;
  htim15.Init.AutoReloadPreload = TIM_AUTORELOAD_PRELOAD_DISABLE;
  if (HAL_TIM_PWM_Init(&htim15) != HAL_OK)
  {
    Error_Handler();
  }
  sMasterConfig.MasterOutputTrigger = TIM_TRGO_RESET;
  sMasterConfig.MasterSlaveMode = TIM_MASTERSLAVEMODE_DISABLE;
  if (HAL_TIMEx_MasterConfigSynchronization(&htim15, &sMasterConfig) != HAL_OK)
  {
    Error_Handler();
  }
  sConfigOC.OCMode = TIM_OCMODE_PWM1;
  sConfigOC.Pulse = 0;
  sConfigOC.OCPolarity = TIM_OCPOLARITY_HIGH;
  sConfigOC.OCNPolarity = TIM_OCNPOLARITY_HIGH;
  sConfigOC.OCFastMode = TIM_OCFAST_DISABLE;
  sConfigOC.OCIdleState = TIM_OCIDLESTATE_RESET;
  sConfigOC.OCNIdleState = TIM_OCNIDLESTATE_RESET;
  if (HAL_TIM_PWM_ConfigChannel(&htim15, &sConfigOC, TIM_CHANNEL_1) != HAL_OK)
  {
    Error_Handler();
  }
  if (HAL_TIM_PWM_ConfigChannel(&htim15, &sConfigOC, TIM_CHANNEL_2) != HAL_OK)
  {
    Error_Handler();
  }
  sBreakDeadTimeConfig.OffStateRunMode = TIM_OSSR_DISABLE;
  sBreakDeadTimeConfig.OffStateIDLEMode = TIM_OSSI_DISABLE;
  sBreakDeadTimeConfig.LockLevel = TIM_LOCKLEVEL_OFF;
  sBreakDeadTimeConfig.DeadTime = 0;
  sBreakDeadTimeConfig.BreakState = TIM_BREAK_DISABLE;
  sBreakDeadTimeConfig.BreakPolarity = TIM_BREAKPOLARITY_HIGH;
  sBreakDeadTimeConfig.BreakFilter = 0;
  sBreakDeadTimeConfig.AutomaticOutput = TIM_AUTOMATICOUTPUT_DISABLE;
  if (HAL_TIMEx_ConfigBreakDeadTime(&htim15, &sBreakDeadTimeConfig) != HAL_OK)
  {
    Error_Handler();
  }
  HAL_TIM_MspPostInit(&htim15);

}

static void MX_UART8_Init(void)
{

  huart8.Instance = UART8;
  huart8.Init.BaudRate = 57600;
  huart8.Init.WordLength = UART_WORDLENGTH_9B;
  huart8.Init.StopBits = UART_STOPBITS_1;
  huart8.Init.Parity = UART_PARITY_EVEN;
  huart8.Init.Mode = UART_MODE_TX_RX;
  huart8.Init.HwFlowCtl = UART_HWCONTROL_NONE;
  huart8.Init.OverSampling = UART_OVERSAMPLING_16;
  huart8.Init.OneBitSampling = UART_ONE_BIT_SAMPLE_DISABLE;
  huart8.Init.ClockPrescaler = UART_PRESCALER_DIV1;
  huart8.AdvancedInit.AdvFeatureInit = UART_ADVFEATURE_NO_INIT;
  if (HAL_UART_Init(&huart8) != HAL_OK)
  {
    Error_Handler();
  }
  if (HAL_UARTEx_SetTxFifoThreshold(&huart8, UART_TXFIFO_THRESHOLD_1_8) != HAL_OK)
  {
    Error_Handler();
  }
  if (HAL_UARTEx_SetRxFifoThreshold(&huart8, UART_RXFIFO_THRESHOLD_1_8) != HAL_OK)
  {
    Error_Handler();
  }
  if (HAL_UARTEx_DisableFifoMode(&huart8) != HAL_OK)
  {
    Error_Handler();
  }

}

static void MX_USART2_UART_Init(void)
{

  huart2.Instance = USART2;
  huart2.Init.BaudRate = 1000000;
  huart2.Init.WordLength = UART_WORDLENGTH_8B;
  huart2.Init.StopBits = UART_STOPBITS_1;
  huart2.Init.Parity = UART_PARITY_NONE;
  huart2.Init.Mode = UART_MODE_TX_RX;
  huart2.Init.HwFlowCtl = UART_HWCONTROL_NONE;
  huart2.Init.OverSampling = UART_OVERSAMPLING_16;
  huart2.Init.OneBitSampling = UART_ONE_BIT_SAMPLE_DISABLE;
  huart2.Init.ClockPrescaler = UART_PRESCALER_DIV1;
  huart2.AdvancedInit.AdvFeatureInit = UART_ADVFEATURE_NO_INIT;
  if (HAL_UART_Init(&huart2) != HAL_OK)
  {
    Error_Handler();
  }
  if (HAL_UARTEx_SetTxFifoThreshold(&huart2, UART_TXFIFO_THRESHOLD_1_8) != HAL_OK)
  {
    Error_Handler();
  }
  if (HAL_UARTEx_SetRxFifoThreshold(&huart2, UART_RXFIFO_THRESHOLD_1_8) != HAL_OK)
  {
    Error_Handler();
  }
  if (HAL_UARTEx_DisableFifoMode(&huart2) != HAL_OK)
  {
    Error_Handler();
  }

}

static void MX_DMA_Init(void)
{

  /* DMA controller clock enable */
  __HAL_RCC_DMA1_CLK_ENABLE();
  __HAL_RCC_DMA2_CLK_ENABLE();

  /* Configure DMA request hdma_memtomem_dma2_stream0 on DMA2_Stream0 */
  hdma_memtomem_dma2_stream0.Instance = DMA2_Stream0;
  hdma_memtomem_dma2_stream0.Init.Request = DMA_REQUEST_MEM2MEM;
  hdma_memtomem_dma2_stream0.Init.Direction = DMA_MEMORY_TO_MEMORY;
  hdma_memtomem_dma2_stream0.Init.PeriphInc = DMA_PINC_ENABLE;
  hdma_memtomem_dma2_stream0.Init.MemInc = DMA_MINC_ENABLE;
  hdma_memtomem_dma2_stream0.Init.PeriphDataAlignment = DMA_PDATAALIGN_BYTE;
  hdma_memtomem_dma2_stream0.Init.MemDataAlignment = DMA_MDATAALIGN_BYTE;
  hdma_memtomem_dma2_stream0.Init.Mode = DMA_NORMAL;
  hdma_memtomem_dma2_stream0.Init.Priority = DMA_PRIORITY_VERY_HIGH;
  hdma_memtomem_dma2_stream0.Init.FIFOMode = DMA_FIFOMODE_ENABLE;
  hdma_memtomem_dma2_stream0.Init.FIFOThreshold = DMA_FIFO_THRESHOLD_FULL;
  hdma_memtomem_dma2_stream0.Init.MemBurst = DMA_MBURST_SINGLE;
  hdma_memtomem_dma2_stream0.Init.PeriphBurst = DMA_PBURST_SINGLE;
  if (HAL_DMA_Init(&hdma_memtomem_dma2_stream0) != HAL_OK)
  {
    Error_Handler( );
  }

  /* DMA interrupt init */
  /* DMA1_Stream2_IRQn interrupt configuration */
  HAL_NVIC_SetPriority(DMA1_Stream2_IRQn, 5, 0);
  HAL_NVIC_EnableIRQ(DMA1_Stream2_IRQn);
  /* DMA1_Stream3_IRQn interrupt configuration */
  HAL_NVIC_SetPriority(DMA1_Stream3_IRQn, 5, 0);
  HAL_NVIC_EnableIRQ(DMA1_Stream3_IRQn);
  /* DMA1_Stream4_IRQn interrupt configuration */
  HAL_NVIC_SetPriority(DMA1_Stream4_IRQn, 5, 0);
  HAL_NVIC_EnableIRQ(DMA1_Stream4_IRQn);
  /* DMA1_Stream5_IRQn interrupt configuration */
  HAL_NVIC_SetPriority(DMA1_Stream5_IRQn, 5, 0);
  HAL_NVIC_EnableIRQ(DMA1_Stream5_IRQn);
  /* DMA1_Stream6_IRQn interrupt configuration */
  HAL_NVIC_SetPriority(DMA1_Stream6_IRQn, 5, 0);
  HAL_NVIC_EnableIRQ(DMA1_Stream6_IRQn);
  /* DMA1_Stream7_IRQn interrupt configuration */
  HAL_NVIC_SetPriority(DMA1_Stream7_IRQn, 5, 0);
  HAL_NVIC_EnableIRQ(DMA1_Stream7_IRQn);
  /* DMA2_Stream0_IRQn interrupt configuration */
  HAL_NVIC_SetPriority(DMA2_Stream0_IRQn, 5, 0);
  HAL_NVIC_EnableIRQ(DMA2_Stream0_IRQn);

}

static void MX_GPIO_Init(void)
{
  GPIO_InitTypeDef GPIO_InitStruct = {0};

  /* GPIO Ports Clock Enable */
  __HAL_RCC_GPIOE_CLK_ENABLE();
  __HAL_RCC_GPIOH_CLK_ENABLE();
  __HAL_RCC_GPIOC_CLK_ENABLE();
  __HAL_RCC_GPIOA_CLK_ENABLE();
  __HAL_RCC_GPIOB_CLK_ENABLE();
  __HAL_RCC_GPIOD_CLK_ENABLE();

  /*Configure GPIO pin Output Level */
  HAL_GPIO_WritePin(GPIOE, LED2_Pin|NEW_SAMPLES_OUTPUT_Pin|LED1_Pin, GPIO_PIN_RESET);

  /*Configure GPIO pin Output Level */
  HAL_GPIO_WritePin(GPIOC, MOTOR_RIGHT_DIR_Pin|MOTOR_LEFT_DIR_Pin, GPIO_PIN_RESET);

  /*Configure GPIO pin Output Level */
  HAL_GPIO_WritePin(CS_IMU_GPIO_Port, CS_IMU_Pin, GPIO_PIN_RESET);

  /*Configure GPIO pin Output Level */
  HAL_GPIO_WritePin(GPIOD, CONTROL_TASK_TICK_Pin|RS485_EN_Pin|GPIO_PIN_5|GPIO_PIN_7, GPIO_PIN_RESET);

  /*Configure GPIO pins : LED2_Pin LED1_Pin */
  GPIO_InitStruct.Pin = LED2_Pin|LED1_Pin;
  GPIO_InitStruct.Mode = GPIO_MODE_OUTPUT_PP;
  GPIO_InitStruct.Pull = GPIO_NOPULL;
  GPIO_InitStruct.Speed = GPIO_SPEED_FREQ_LOW;
  HAL_GPIO_Init(GPIOE, &GPIO_InitStruct);

  /*Configure GPIO pins : MOTOR_RIGHT_DIR_Pin MOTOR_LEFT_DIR_Pin */
  GPIO_InitStruct.Pin = MOTOR_RIGHT_DIR_Pin|MOTOR_LEFT_DIR_Pin;
  GPIO_InitStruct.Mode = GPIO_MODE_OUTPUT_PP;
  GPIO_InitStruct.Pull = GPIO_NOPULL;
  GPIO_InitStruct.Speed = GPIO_SPEED_FREQ_LOW;
  HAL_GPIO_Init(GPIOC, &GPIO_InitStruct);

  /*Configure GPIO pin : UART_RESET_INTERRUPT_Pin */
  GPIO_InitStruct.Pin = UART_RESET_INTERRUPT_Pin;
  GPIO_InitStruct.Mode = GPIO_MODE_IT_RISING_FALLING;
  GPIO_InitStruct.Pull = GPIO_PULLDOWN;
  HAL_GPIO_Init(UART_RESET_INTERRUPT_GPIO_Port, &GPIO_InitStruct);

  /*Configure GPIO pin : NEW_SAMPLES_OUTPUT_Pin */
  GPIO_InitStruct.Pin = NEW_SAMPLES_OUTPUT_Pin;
  GPIO_InitStruct.Mode = GPIO_MODE_OUTPUT_PP;
  GPIO_InitStruct.Pull = GPIO_PULLDOWN;
  GPIO_InitStruct.Speed = GPIO_SPEED_FREQ_LOW;
  HAL_GPIO_Init(NEW_SAMPLES_OUTPUT_GPIO_Port, &GPIO_InitStruct);

  /*Configure GPIO pin : CS_IMU_Pin */
  GPIO_InitStruct.Pin = CS_IMU_Pin;
  GPIO_InitStruct.Mode = GPIO_MODE_OUTPUT_PP;
  GPIO_InitStruct.Pull = GPIO_NOPULL;
  GPIO_InitStruct.Speed = GPIO_SPEED_FREQ_LOW;
  HAL_GPIO_Init(CS_IMU_GPIO_Port, &GPIO_InitStruct);

  /*Configure GPIO pins : CONTROL_TASK_TICK_Pin RS485_EN_Pin PD5 PD7 */
  GPIO_InitStruct.Pin = CONTROL_TASK_TICK_Pin|RS485_EN_Pin|GPIO_PIN_5|GPIO_PIN_7;
  GPIO_InitStruct.Mode = GPIO_MODE_OUTPUT_PP;
  GPIO_InitStruct.Pull = GPIO_NOPULL;
  GPIO_InitStruct.Speed = GPIO_SPEED_FREQ_LOW;
  HAL_GPIO_Init(GPIOD, &GPIO_InitStruct);

  /*Configure GPIO pins : PA9 PA10 */
  GPIO_InitStruct.Pin = GPIO_PIN_9|GPIO_PIN_10;
  GPIO_InitStruct.Mode = GPIO_MODE_AF_PP;
  GPIO_InitStruct.Pull = GPIO_NOPULL;
  GPIO_InitStruct.Speed = GPIO_SPEED_FREQ_LOW;
  GPIO_InitStruct.Alternate = GPIO_AF7_USART1;
  HAL_GPIO_Init(GPIOA, &GPIO_InitStruct);

  /* EXTI interrupt init*/
  HAL_NVIC_SetPriority(UART_RESET_INTERRUPT_EXTI_IRQn, 5, 0);
  HAL_NVIC_EnableIRQ(UART_RESET_INTERRUPT_EXTI_IRQn);

}

void StartDefaultTask(void *argument)
{
  for(;;)
  {
    osDelay(1);
  }
}

/* Callback01 function */
void Callback01(void *argument)
{
}

void HAL_TIM_PeriodElapsedCallback(TIM_HandleTypeDef *htim)
{
  if (htim->Instance == TIM6)
  {
    HAL_IncTick();
  }
}

void Error_Handler(void)
{
  __disable_irq();
  while (1)
  {
  }
}
